# ATSAM4ExC register map
Vendor: Atmel; Series: SAM4E; File version: 0
CPU: CM4 r0p1, selectable endian, MPU, FPU, 4 interrupt priority bits
Registers are 32-bit, read-write, reset 0x0 unless marked. A register's access mark holds for its fields unless they carry their own. Offsets are from the block's base; [hi:lo] are bit positions.

## DACC — Digital-to-Analog Converter Controller
Base 0x400B8000; register names take the prefix DACC_
0x00 CR wo reset not defined — Control Register
  [0] SWRST — Software Reset
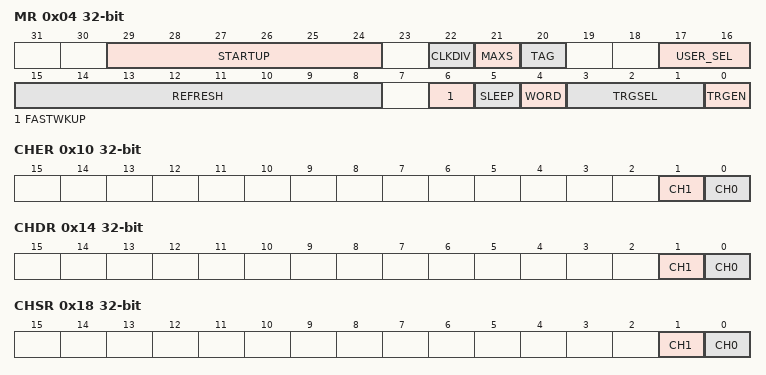
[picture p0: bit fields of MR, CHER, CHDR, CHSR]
0x04 MR — Mode Register
  [29:24] STARTUP — Startup Time Selection
    0=0 periods of DACClock; 1=8 periods of DACClock; 2=16 periods of DACClock; 3=24 periods of DACClock; 4=64 periods of DACClock; 5=80 periods of DACClock; 6=96 periods of DACClock; 7=112 periods of DACClock; 8=512 periods of DACClock; 9=576 periods of DACClock; 10=640 periods of DACClock; 11=704 periods of DACClock; 12=768 periods of DACClock; 13=832 periods of DACClock; 14=896 periods of DACClock; 15=960 periods of DACClock; 16=1024 periods of DACClock; 17=1088 periods of DACClock; 18=1152 periods of DACClock; 19=1216 periods of DACClock; 20=1280 periods of DACClock; 21=1344 periods of DACClock; 22=1408 periods of DACClock; 23=1472 periods of DACClock; 24=1536 periods of DACClock; 25=1600 periods of DACClock; 26=1664 periods of DACClock; 27=1728 periods of DACClock; 28=1792 periods of DACClock; 29=1856 periods of DACClock; 30=1920 periods of DACClock; 31=1984 periods of DACClock; 32=2048 periods of DACClock; 33=2112 periods of DACClock; 34=2176 periods of DACClock; 35=2240 periods of DACClock; 36=2304 periods of DACClock; 37=2368 periods of DACClock; 38=2432 periods of DACClock; 39=2496 periods of DACClock; 40=2560 periods of DACClock; 41=2624 periods of DACClock; 42=2688 periods of DACClock; 43=2752 periods of DACClock; 44=2816 periods of DACClock; 45=2880 periods of DACClock; 46=2944 periods of DACClock; 47=3008 periods of DACClock; 48=3072 periods of DACClock; 49=3136 periods of DACClock; 50=3200 periods of DACClock; 51=3264 periods of DACClock; 52=3328 periods of DACClock; 53=3392 periods of DACClock; 54=3456 periods of DACClock; 55=3520 periods of DACClock; 56=3584 periods of DACClock; 57=3648 periods of DACClock; 58=3712 periods of DACClock; 59=3776 periods of DACClock; 60=3840 periods of DACClock; 61=3904 periods of DACClock; 62=3968 periods of DACClock; 63=4032 periods of DACClock
  [22] CLKDIV — Clock Divider
    0=DIV_2 (The DAC clock is MCK divided by 2); 1=DIV_4 (The DAC clock is MCK divided by 4 (to be used when MCK frequency is above 100MHz))
  [21] MAXS — Max Speed Mode
    0=NORMAL (Normal mode); 1=MAXIMUM (Maximum speed mode enabled)
  [20] TAG — Tag Selection Mode
    0=DIS (Tag selection mode disabled. Using USER_SEL to select the channel for the conversion.); 1=EN (Tag selection mode enabled)
  [17:16] USER_SEL — User Channel Selection
    0=CHANNEL0; 1=CHANNEL1
  [15:8] REFRESH — Automatic Refresh Period
  [6] FASTWKUP — Fast Wake-up Mode
    0=STAMODE (Normal sleep mode: the sleep mode is defined by the SLEEP bit. Voltage reference is OFF between conversions.); 1=FASTWAKEUP (Fast wake-up after sleep mode: voltage reference is kept ON between conversions; DAC core is OFF)
  [5] SLEEP — Sleep Mode
    0=DISABLED (Normal mode: the DAC core and reference voltage circuitry are kept ON between conversions.); 1=ENABLED (Sleep mode: the DAC core and/or reference voltage circuitry are OFF between conversions.)
  [4] WORD — Word Transfer
    0=HALF (Half-word transfer); 1=WORD (Word transfer)
  [3:1] TRGSEL — Trigger Selection
    0=External trigger; 1=TIO Output of the Timer Counter Channel 0; 2=TIO Output of the Timer Counter Channel 1; 3=TIO Output of the Timer Counter Channel 2; 4=PWM Event Line 0; 5=PWM Event Line 1
  [0] TRGEN — Trigger Enable
    0=DIS (External trigger mode disabled. DACC in free-running mode.); 1=EN (External trigger mode enabled.)
0x10 CHER wo reset not defined — Channel Enable Register
  [1] CH1 — Channel 1 Enable
  [0] CH0 — Channel 0 Enable
0x14 CHDR wo reset not defined — Channel Disable Register
  [1] CH1 — Channel 1 Disable
  [0] CH0 — Channel 0 Disable
0x18 CHSR ro — Channel Status Register
  [1] CH1 — Channel 1 Status
  [0] CH0 — Channel 0 Status
0x20 CDR wo — Conversion Data Register
  [31:0] DATA — Data to Convert
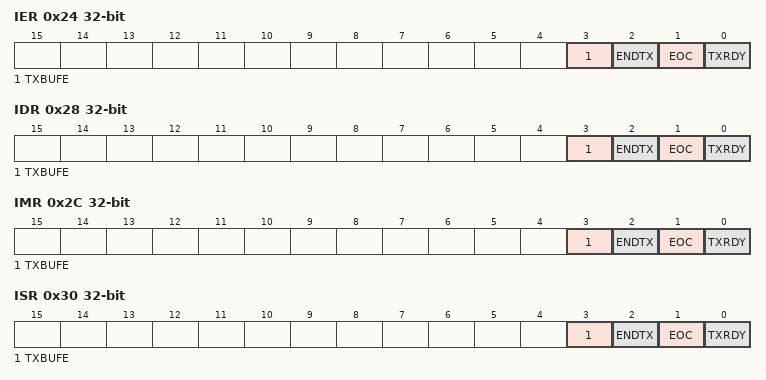
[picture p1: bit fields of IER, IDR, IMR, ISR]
0x24 IER wo reset not defined — Interrupt Enable Register
  [3] TXBUFE — Transmit Buffer Empty Interrupt Enable
  [2] ENDTX — End of Transmit Buffer Interrupt Enable
  [1] EOC — End of Conversion Interrupt Enable
  [0] TXRDY — Transmit Ready Interrupt Enable
0x28 IDR wo reset not defined — Interrupt Disable Register
  [3] TXBUFE — Transmit Buffer Empty Interrupt Disable
  [2] ENDTX — End of Transmit Buffer Interrupt Disable
  [1] EOC — End of Conversion Interrupt Disable
  [0] TXRDY — Transmit Ready Interrupt Disable.
0x2C IMR ro — Interrupt Mask Register
  [3] TXBUFE — Transmit Buffer Empty Interrupt Mask
  [2] ENDTX — End of Transmit Buffer Interrupt Mask
  [1] EOC — End of Conversion Interrupt Mask
  [0] TXRDY — Transmit Ready Interrupt Mask
0x30 ISR ro — Interrupt Status Register
  [3] TXBUFE — Transmit Buffer Empty
  [2] ENDTX — End of DMA Interrupt Flag
  [1] EOC — End of Conversion Interrupt Flag
  [0] TXRDY — Transmit Ready Interrupt Flag
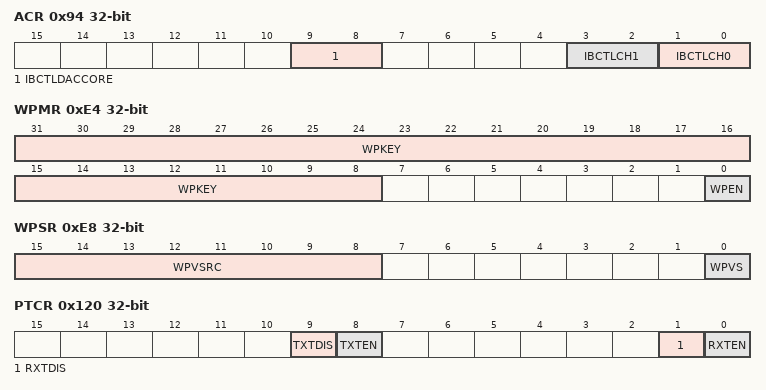
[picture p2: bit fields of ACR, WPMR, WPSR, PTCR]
0x94 ACR — Analog Current Register
  [9:8] IBCTLDACCORE — Bias Current Control for DAC Core
  [3:2] IBCTLCH1 — Analog Output Current Control
  [1:0] IBCTLCH0 — Analog Output Current Control
0xE4 WPMR — Write Protection Mode Register
  [31:8] WPKEY — Write Protection KEY
    0x444143=PASSWD (Writing any other value in this field aborts the write operation of the WPEN bit.Always reads as 0.)
  [0] WPEN — Write Protection Enable
0xE8 WPSR ro — Write Protection Status Register
  [15:8] WPVSRC — Write Protection Violation Source
  [0] WPVS — Write Protection Violation Status
0x108 TPR — Transmit Pointer Register
  [31:0] TXPTR — Transmit Counter Register
0x10C TCR — Transmit Counter Register
  [15:0] TXCTR
0x118 TNPR — Transmit Next Pointer Register
  [31:0] TXNPTR — Transmit Next Pointer
0x11C TNCR — Transmit Next Counter Register
  [15:0] TXNCTR — Transmit Counter Next
0x120 PTCR wo — Transfer Control Register
  [9] TXTDIS — Transmitter Transfer Disable
  [8] TXTEN — Transmitter Transfer Enable
  [1] RXTDIS — Receiver Transfer Disable
  [0] RXTEN — Receiver Transfer Enable
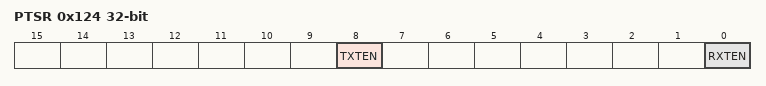
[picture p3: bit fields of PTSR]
0x124 PTSR ro — Transfer Status Register
  [8] TXTEN — Transmitter Transfer Enable
  [0] RXTEN — Receiver Transfer Enable
